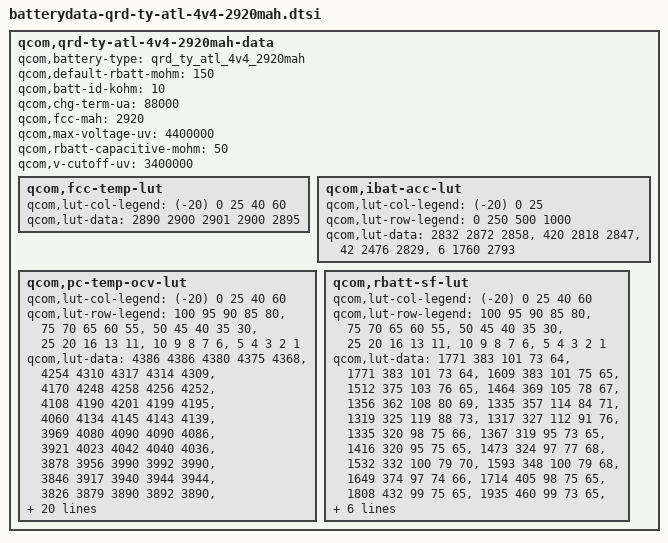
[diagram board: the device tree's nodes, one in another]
/* Copyright (c) 2015, The Linux Foundation. All rights reserved.
 *
 * This program is free software; you can redistribute it and/or modify
 * it under the terms of the GNU General Public License version 2 and
 * only version 2 as published by the Free Software Foundation.
 *
 * This program is distributed in the hope that it will be useful,
 * but WITHOUT ANY WARRANTY; without even the implied warranty of
 * MERCHANTABILITY or FITNESS FOR A PARTICULAR PURPOSE.  See the
 * GNU General Public License for more details.
 */

qcom,qrd-ty-atl-4v4-2920mah-data {
	qcom,battery-type = "qrd_ty_atl_4v4_2920mah";
	qcom,default-rbatt-mohm = <150>;
	qcom,batt-id-kohm = <10>;
	qcom,chg-term-ua = <88000>;
	qcom,fcc-mah = <2920>;
	qcom,max-voltage-uv = <4400000>;
	qcom,rbatt-capacitive-mohm = <50>;
	qcom,v-cutoff-uv = <3400000>;

	qcom,fcc-temp-lut {
		qcom,lut-col-legend = <(-20) 0 25 40 60>;
		qcom,lut-data = <2890 2900 2901 2900 2895>;
	};

	qcom,ibat-acc-lut {
		qcom,lut-col-legend = <(-20) 0 25>;
		qcom,lut-row-legend = <0 250 500 1000>;
		qcom,lut-data = <2832 2872 2858>,
				<420 2818 2847>,
				<42 2476 2829>,
				<6 1760 2793>;
	};

	qcom,pc-temp-ocv-lut {
		qcom,lut-col-legend = <(-20) 0 25 40 60>;
		qcom,lut-row-legend = <100 95 90 85 80>,
					<75 70 65 60 55>,
					<50 45 40 35 30>,
					<25 20 16 13 11>,
					<10 9 8 7 6>,
					<5 4 3 2 1>;
		qcom,lut-data = <4386 4386 4380 4375 4368>,
				<4254 4310 4317 4314 4309>,
				<4170 4248 4258 4256 4252>,
				<4108 4190 4201 4199 4195>,
				<4060 4134 4145 4143 4139>,
				<3969 4080 4090 4090 4086>,
				<3921 4023 4042 4040 4036>,
				<3878 3956 3990 3992 3990>,
				<3846 3917 3940 3944 3944>,
				<3826 3879 3890 3892 3890>,
				<3810 3847 3857 3858 3857>,
				<3797 3820 3831 3832 3830>,
				<3783 3798 3809 3810 3809>,
				<3770 3784 3790 3791 3790>,
				<3754 3772 3773 3772 3766>,
				<3738 3757 3754 3748 3738>,
				<3718 3738 3736 3728 3716>,
				<3699 3718 3716 3708 3694>,
				<3682 3704 3696 3688 3676>,
				<3666 3696 3688 3681 3670>,
				<3658 3692 3686 3680 3668>,
				<3650 3688 3684 3678 3668>,
				<3639 3684 3682 3676 3666>,
				<3626 3678 3680 3672 3662>,
				<3608 3668 3672 3664 3650>,
				<3586 3646 3648 3637 3620>,
				<3554 3608 3604 3592 3574>,
				<3506 3554 3545 3533 3514>,
				<3433 3476 3464 3452 3434>,
				<3304 3352 3339 3324 3307>;

	};

	qcom,rbatt-sf-lut {
		qcom,lut-col-legend = <(-20) 0 25 40 60>;
		qcom,lut-row-legend = <100 95 90 85 80>,
					<75 70 65 60 55>,
					<50 45 40 35 30>,
					<25 20 16 13 11>,
					<10 9 8 7 6>,
					<5 4 3 2 1>;
		qcom,lut-data = <1771 383 101 73 64>,
				<1771 383 101 73 64>,
				<1609 383 101 75 65>,
				<1512 375 103 76 65>,
				<1464 369 105 78 67>,
				<1356 362 108 80 69>,
				<1335 357 114 84 71>,
				<1319 325 119 88 73>,
				<1317 327 112 91 76>,
				<1335 320 98 75 66>,
				<1367 319 95 73 65>,
				<1416 320 95 75 65>,
				<1473 324 97 77 68>,
				<1532 332 100 79 70>,
				<1593 348 100 79 68>,
				<1649 374 97 74 66>,
				<1714 405 98 75 65>,
				<1808 432 99 75 65>,
				<1935 460 99 73 65>,
				<2031 479 99 74 65>,
				<2039 479 100 75 66>,
				<1949 475 101 76 68>,
				<2084 490 103 78 70>,
				<2269 508 107 81 73>,
				<2500 527 109 81 72>,
				<2801 546 108 78 67>,
				<3202 569 105 77 67>,
				<3784 611 111 80 69>,
				<4764 673 117 85 75>,
				<9528 892 159 119 95>;
	};
};
